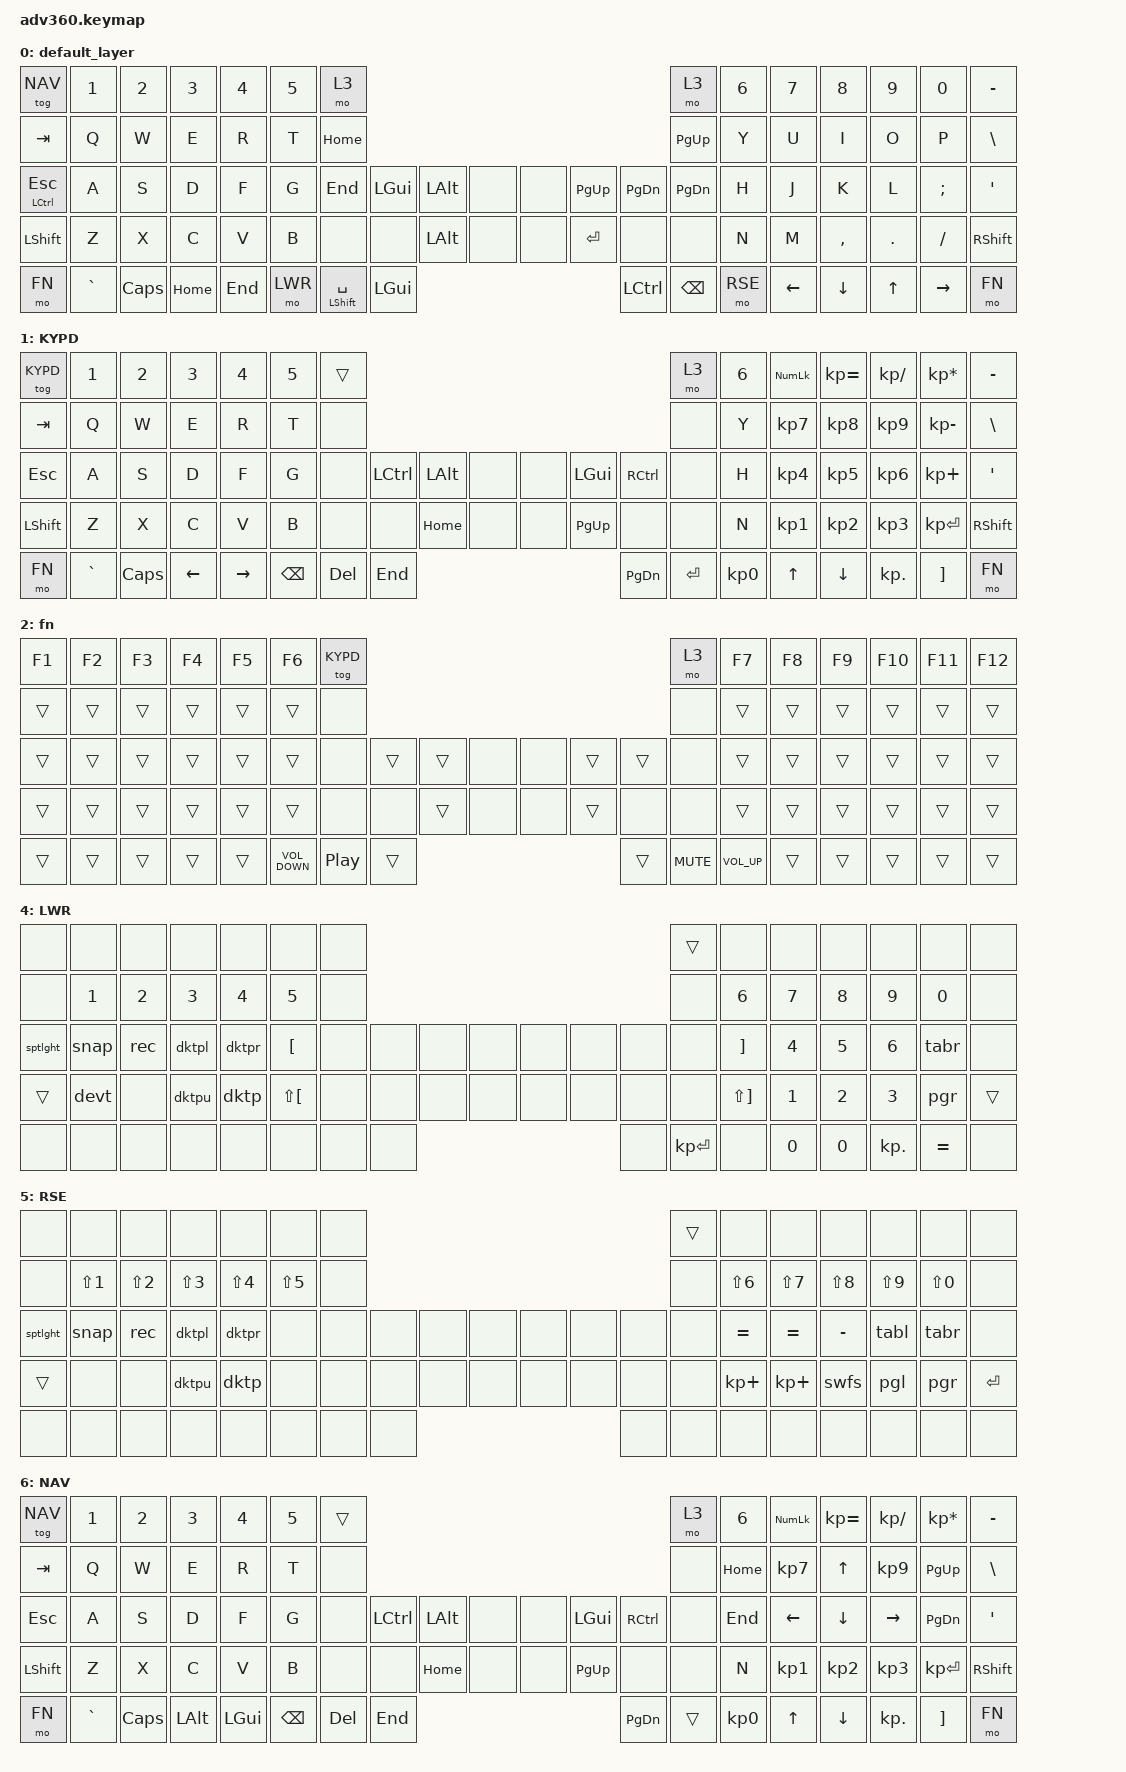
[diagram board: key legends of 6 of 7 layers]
#include <behaviors.dtsi>
#include <dt-bindings/zmk/keys.h>
#include <dt-bindings/zmk/bt.h>
#include <dt-bindings/zmk/rgb.h>
#include <dt-bindings/zmk/backlight.h>

#define DEFAULT 0
#define KYPD    1
#define FN      2
#define MOD     3
#define LWR     4
#define RSE     5
#define NAV     6

/ {
    behaviors {
      #include "macros.dtsi"
      #include "custommacros.dtsi"
      #include "version.dtsi"
      #ifndef VERSION_MACRO
      macro_ver: macro_ver {
        compatible = "zmk,behavior-macro";
        label = "macro_version";
        #binding-cells = <0>;
        bindings = <&kp RET>;
      };
      #endif

      hm: homerow_mods {
          compatible = "zmk,behavior-hold-tap";
          label = "HOMEROW_MODS";
          #binding-cells = <2>;
          tapping-term-ms = <200>;
          quick_tap_ms = <175>;
          flavor = "tap-preferred";
          bindings = <&kp>, <&kp>;
      };
    };

  keymap {
    compatible = "zmk,keymap";

    default_layer {
      bindings = <
        &tog NAV     &kp N1    &kp N2   &kp N3   &kp N4     &kp N5 &mo 3                                                                        &mo 3     &kp N6 &kp N7   &kp N8    &kp N9   &kp N0    &kp MINUS
        &kp TAB      &kp Q     &kp W    &kp E    &kp R      &kp T  &kp HOME                                                                     &kp PG_UP &kp Y  &kp U    &kp I     &kp O    &kp P     &kp BSLH
        &hm LCTL ESC &kp A     &kp S    &kp D    &kp F      &kp G  &kp END          &kp LGUI &kp LALT &none &none &kp PG_UP &kp PG_DN           &kp PG_DN &kp H  &kp J    &kp K     &kp L    &kp SEMI  &kp SQT
        &kp LSHFT    &kp Z     &kp X    &kp C    &kp V      &kp B         &none    &none     &kp LALT &none &none &kp ENTER &none     &none               &kp N  &kp M    &kp COMMA &kp DOT  &kp FSLH  &kp RSHFT
        &mo FN       &kp GRAVE &kp CAPS &kp HOME &kp END                &mo LWR  &hm LSHFT SPACE &kp LGUI         &kp LCTRL &kp BSPC &mo RSE                 &kp LEFT &kp DOWN  &kp UP   &kp RIGHT &mo FN
      >;
    };
    KYPD {
      bindings = <           
        &tog KYPD &kp N1    &kp N2   &kp N3   &kp N4     &kp N5 &trans                                                                       &mo 3 &kp N6 &kp KP_NUM &kp KP_EQUAL &kp KP_DIVIDE &kp KP_MULTIPLY &kp MINUS
        &kp TAB   &kp Q     &kp W    &kp E    &kp R      &kp T  &none                                                                        &none &kp Y  &kp KP_N7  &kp KP_N8    &kp KP_N9     &kp KP_MINUS    &kp BSLH
        &kp ESC   &kp A     &kp S    &kp D    &kp F      &kp G  &none           &kp LCTRL &kp LALT &none &none &kp LGUI  &kp RCTRL           &none &kp H  &kp KP_N4  &kp KP_N5    &kp KP_N6     &kp KP_PLUS     &kp SQT
        &kp LSHFT &kp Z     &kp X    &kp C    &kp V      &kp B         &none    &none     &kp HOME &none &none &kp PG_UP &none     &none           &kp N  &kp KP_N1  &kp KP_N2    &kp KP_N3     &kp KP_ENTER    &kp RSHFT
        &mo FN     &kp GRAVE &kp CAPS &kp LEFT &kp RIGHT                &kp BSPC &kp DEL   &kp END              &kp PG_DN &kp ENTER &kp KP_N0              &kp UP     &kp DOWN     &kp KP_DOT    &kp RBKT        &mo FN
      >;
    };
    fn {
      bindings = <
        &kp F1 &kp F2 &kp F3 &kp F4 &kp F5 &kp F6 &tog KYPD                                                       &mo 3 &kp F7 &kp F8 &kp F9 &kp F10 &kp F11 &kp F12
        &trans &trans &trans &trans &trans &trans  &none                                                       &none &trans &trans &trans &trans  &trans  &trans
        &trans &trans &trans &trans &trans &trans  &none        &trans &trans &none &none &trans &trans        &none &trans &trans &trans &trans  &trans  &trans
        &trans &trans &trans &trans &trans &trans        &none  &none  &trans &none &none &trans &none  &none        &trans &trans &trans &trans  &trans  &trans
        &trans &trans &trans &trans &trans               &kp C_VOLUME_DOWN &kp C_PLAY_PAUSE &trans             &trans &kp C_MUTE &kp C_VOLUME_UP &trans &trans &trans  &trans  &trans
      >;
    };
    mod {
      bindings = <
        &none &bt BT_SEL 0 &bt BT_SEL 1 &bt BT_SEL 2 &bt BT_SEL 3 &bt BT_SEL 4 &trans &none                                                                                                          &trans          &bt BT_SEL 0 &bt BT_SEL 1 &bt BT_SEL 2 &bt BT_SEL 3 &bt BT_SEL 4 &none
        &none &none        &none        &none        &none        &none        &bootloader                                                                                                    &bootloader            &none        &none        &none        &none        &none        &none
        &none &none        &none        &none        &none        &none        &rgb_ug RGB_MEFS_CMD 5                 &bt BT_CLR &bt BT_CLR &none &none &bt BT_CLR &bt BT_CLR                 &rgb_ug RGB_MEFS_CMD 5 &none        &none        &none        &none        &none        &none
        &none &none        &none        &none        &none        &none                               &none           &none      &none      &none &none &none      &none      &none                                  &none        &none        &none        &none        &none        &none
        &none &none        &none        &bl BL_INC   &bl BL_DEC                                       &rgb_ug RGB_TOG &bl BL_TOG &none                  &none      &bl BL_TOG &rgb_ug RGB_TOG                                     &bl BL_INC   &bl BL_DEC   &none        &none        &none
      >;
    };
    LWR {
      bindings = <
        &none    &none        &none        &none        &none        &none        &none                                                                                                                &trans           &none        &none        &none        &none         &none               &none
        &none    &kp N1       &kp N2       &kp N3       &kp N4       &kp N5       &none                                                                                                                &none            &kp N6       &kp N7       &kp N8       &kp N9        &kp N0              &none
        &sptlght &snap        &rec         &dktpl       &dktpr       &kp LBKT     &none                 &none &none &none &none &none &none                                                            &none            &kp RBKT     &kp N4       &kp N5       &kp N6        &tabr               &none
        &trans   &devt        &none        &dktpu       &dktp        &kp LS(LBKT)                 &none &none &none &none &none &none &none &none                                                                       &kp LS(RBKT) &kp N1       &kp N2       &kp N3        &pgr                &trans        
        &none    &none        &none        &none        &none                                     &none &none &none             &none &kp KP_ENTER &none                                                                             &kp N0       &kp N0       &kp KP_DOT    &kp EQUAL           &none
      >;
    };
    RSE {
      bindings = <
        &none    &none        &none        &none        &none        &none        &none                                                                                                                &trans           &none        &none        &none        &none         &none               &none
        &none    &kp LS(N1)   &kp LS(N2)   &kp LS(N3)   &kp LS(N4)   &kp LS(N5)   &none                                                                                                                &none            &kp LS(N6)   &kp LS(N7)   &kp LS(N8)   &kp LS(N9)    &kp LS(N0)          &none
        &sptlght &snap        &rec         &dktpl       &dktpr       &none        &none                 &none &none &none &none &none &none                                                            &none            &kp EQUAL    &kp EQUAL    &kp MINUS    &tabl         &tabr               &none
        &trans   &none        &none        &dktpu       &dktp       &none                         &none &none &none &none &none &none &none &none                                                                       &kp KP_PLUS  &kp KP_PLUS  &swfs        &pgl          &pgr                &kp ENTER        
        &none    &none        &none        &none        &none                                     &none &none &none             &none &none &none                                                                                    &none        &none        &none         &none               &none
      >;
    };
    NAV {
      bindings = <           
        &tog NAV   &kp N1    &kp N2   &kp N3   &kp N4     &kp N5 &trans                                                                        &mo 3 &kp N6    &kp KP_NUM &kp KP_EQUAL &kp KP_DIVIDE &kp KP_MULTIPLY &kp MINUS
        &kp TAB    &kp Q     &kp W    &kp E    &kp R      &kp T  &none                                                                         &none &kp HOME  &kp KP_N7  &kp UP       &kp KP_N9     &kp PG_UP       &kp BSLH
        &kp ESC    &kp A     &kp S    &kp D    &kp F      &kp G  &none           &kp LCTRL &kp LALT &none &none &kp LGUI  &kp RCTRL            &none &kp END   &kp LEFT   &kp DOWN     &kp RIGHT     &kp PG_DN       &kp SQT
        &kp LSHFT  &kp Z     &kp X    &kp C    &kp V      &kp B         &none    &none     &kp HOME &none &none &kp PG_UP &none     &none            &kp N     &kp KP_N1  &kp KP_N2    &kp KP_N3     &kp KP_ENTER    &kp RSHFT
        &mo FN     &kp GRAVE &kp CAPS &kp LALT &kp LGUI                &kp BSPC &kp DEL   &kp END              &kp PG_DN &trans &kp KP_N0                      &kp UP     &kp DOWN     &kp KP_DOT    &kp RBKT        &mo FN
      >;
    };
  };
};

